AUTOSAR XML (schema 00047)
package /Fota/ServiceSwComponentTypes
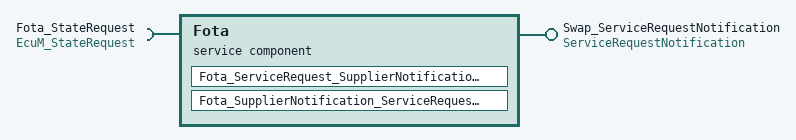
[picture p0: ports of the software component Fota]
  service sw component type Fota
    require port Fota_StateRequest: client-com-spec=RequestReset, required-interface=EcuM_StateRequest
    provide port Swap_ServiceRequestNotification: provided-com-specs=[{operation=Confirmation, queue-length=1}, {operation=Indication, queue-length=1}], provided-interface=ServiceRequestNotification
    behavior InternalBehavior: handle-termination-and-restart=NO-SUPPORT
      operation invoked event OIE_Fota_ServiceRequest_SupplierNotification_Confirmation_Swap_ServiceRequestNotification_Confirmation: start-on-event=Fota_ServiceRequest_SupplierNotification_Confirmation, operation=Swap_ServiceRequestNotification.Confirmation
      operation invoked event OIE_Fota_SupplierNotification_ServiceRequest_Indication_Swap_ServiceRequestNotification_Indication: start-on-event=Fota_SupplierNotification_ServiceRequest_Indication, operation=Swap_ServiceRequestNotification.Indication
      runnable Fota_ServiceRequest_SupplierNotification_Confirmation: can-be-invoked-concurrently=true, symbol=Fota_SupplierNotification_ServiceRequest_Confirmation
        sync call SSCP_Fota_ServiceRequest_SupplierNotification_Confirmation_Fota_StateRequest_RequestReset: operation=Fota_StateRequest.RequestReset
      runnable Fota_SupplierNotification_ServiceRequest_Indication: can-be-invoked-concurrently=true
